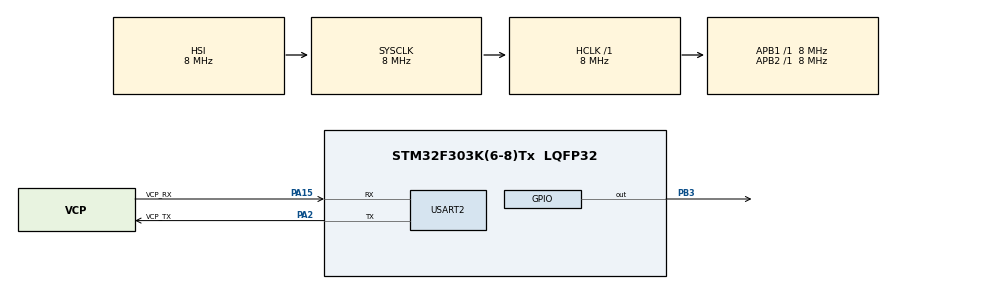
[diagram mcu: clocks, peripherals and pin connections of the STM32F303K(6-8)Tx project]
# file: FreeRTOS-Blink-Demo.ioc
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FREERTOS.Tasks01=blink01,24,128,StartBlink01,Default,NULL,Dynamic,NULL,NULL;blink02,16,128,StartBlink02,Default,NULL,Dynamic,NULL,NULL
Mcu.Family=STM32F3
Mcu.Name=STM32F303K(6-8)Tx
Mcu.Package=LQFP32
NVIC.PriorityGroup=NVIC_PRIORITYGROUP_4
NVIC.TIM6_DAC1_IRQn=true\:0\:0\:false\:false\:true\:false\:false\:true
NVIC.TimeBase=TIM6_DAC1_IRQn
NVIC.TimeBaseIP=TIM6
PA13.GPIO_Label=SWDIO
PA13.Mode=Serial_Wire
PA13.Signal=SYS_JTMS-SWDIO
PA14.GPIO_Label=SWCLK
PA14.Mode=Serial_Wire
PA14.Signal=SYS_JTCK-SWCLK
PA15.GPIO_Label=VCP_RX
PA15.Mode=Asynchronous
PA15.Signal=USART2_RX
PA2.GPIO_Label=VCP_TX
PA2.Mode=Asynchronous
PA2.Signal=USART2_TX
PB3.Signal=GPIO_Output
PF0\ /\ OSC_IN.GPIO_Label=MCO
PF0\ /\ OSC_IN.Mode=HSE-External-Clock-Source
PF0\ /\ OSC_IN.Signal=RCC_OSC_IN
ProjectManager.HeapSize=0x200
ProjectManager.StackSize=0x400
ProjectManager.TargetToolchain=TrueSTUDIO
RCC.AHBFreq_Value=8000000
RCC.APB1Freq_Value=8000000
RCC.APB2Freq_Value=8000000
RCC.CortexFreq_Value=8000000
RCC.HSE_VALUE=8000000
RCC.HSI_VALUE=8000000
RCC.SYSCLKFreq_VALUE=8000000
USART2.VirtualMode-Asynchronous=VM_ASYNC
VP_FREERTOS_VS_CMSIS_V2.Mode=CMSIS_V2
VP_SYS_VS_tim6.Mode=TIM6
board=NUCLEO-F303K8

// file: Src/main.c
/* USER CODE BEGIN Header */
/**
  ******************************************************************************
  * @file           : main.c
  * @brief          : Main program body
  ******************************************************************************
  * @attention
  *
  * <h2><center>&copy; Copyright (c) 2020 STMicroelectronics.
  * All rights reserved.</center></h2>
  *
  * This software component is licensed by ST under Ultimate Liberty license
  * SLA0044, the "License"; You may not use this file except in compliance with
  * the License. You may obtain a copy of the License at:
  *                             www.st.com/SLA0044
  *
  ******************************************************************************
  */
/* USER CODE END Header */

#include "main.h"
#include "cmsis_os.h"
#include "usart.h"
#include "gpio.h"

void SystemClock_Config(void);
void MX_FREERTOS_Init(void);

int main(void)
{

  /* MCU Configuration--------------------------------------------------------*/

  /* Reset of all peripherals, Initializes the Flash interface and the Systick. */
  HAL_Init();

  /* Configure the system clock */
  SystemClock_Config();

  /* Initialize all configured peripherals */
  MX_GPIO_Init();
  MX_USART2_UART_Init();
  /* Init scheduler */
  osKernelInitialize();

  /* Call init function for freertos objects (in freertos.c) */
  MX_FREERTOS_Init();

  /* Start scheduler */
  osKernelStart();

  /* We should never get here as control is now taken by the scheduler */

  /* Infinite loop */
  while (1)
  {

  }
}

void SystemClock_Config(void)
{
  RCC_OscInitTypeDef RCC_OscInitStruct = {0};
  RCC_ClkInitTypeDef RCC_ClkInitStruct = {0};

  /** Initializes the CPU, AHB and APB busses clocks
  */
  RCC_OscInitStruct.OscillatorType = RCC_OSCILLATORTYPE_HSI;
  RCC_OscInitStruct.HSIState = RCC_HSI_ON;
  RCC_OscInitStruct.HSICalibrationValue = RCC_HSICALIBRATION_DEFAULT;
  RCC_OscInitStruct.PLL.PLLState = RCC_PLL_NONE;
  if (HAL_RCC_OscConfig(&RCC_OscInitStruct) != HAL_OK)
  {
    Error_Handler();
  }
  /** Initializes the CPU, AHB and APB busses clocks
  */
  RCC_ClkInitStruct.ClockType = RCC_CLOCKTYPE_HCLK|RCC_CLOCKTYPE_SYSCLK
                              |RCC_CLOCKTYPE_PCLK1|RCC_CLOCKTYPE_PCLK2;
  RCC_ClkInitStruct.SYSCLKSource = RCC_SYSCLKSOURCE_HSI;
  RCC_ClkInitStruct.AHBCLKDivider = RCC_SYSCLK_DIV1;
  RCC_ClkInitStruct.APB1CLKDivider = RCC_HCLK_DIV1;
  RCC_ClkInitStruct.APB2CLKDivider = RCC_HCLK_DIV1;

  if (HAL_RCC_ClockConfig(&RCC_ClkInitStruct, FLASH_LATENCY_0) != HAL_OK)
  {
    Error_Handler();
  }
}

void HAL_TIM_PeriodElapsedCallback(TIM_HandleTypeDef *htim)
{
  if (htim->Instance == TIM6) {
    HAL_IncTick();
  }
}

void Error_Handler(void)
{
}

/************************ (C) COPYRIGHT STMicroelectronics *****END OF FILE****/

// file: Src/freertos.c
/* USER CODE BEGIN Header */
/**
  ******************************************************************************
  * File Name          : freertos.c
  * Description        : Code for freertos applications
  ******************************************************************************
  * @attention
  *
  * <h2><center>&copy; Copyright (c) 2020 STMicroelectronics.
  * All rights reserved.</center></h2>
  *
  * This software component is licensed by ST under Ultimate Liberty license
  * SLA0044, the "License"; You may not use this file except in compliance with
  * the License. You may obtain a copy of the License at:
  *                             www.st.com/SLA0044
  *
  ******************************************************************************
  */
/* USER CODE END Header */

#include "FreeRTOS.h"
#include "task.h"
#include "main.h"
#include "cmsis_os.h"

/* Definitions for blink01 */
osThreadId_t blink01Handle;
const osThreadAttr_t blink01_attributes = {
  .name = "blink01",
  .priority = (osPriority_t) osPriorityNormal,
  .stack_size = 128
};
/* Definitions for blink02 */
osThreadId_t blink02Handle;
const osThreadAttr_t blink02_attributes = {
  .name = "blink02",
  .priority = (osPriority_t) osPriorityBelowNormal,
  .stack_size = 128
};

void StartBlink01(void *argument);
void StartBlink02(void *argument);

void MX_FREERTOS_Init(void); /* (MISRA C 2004 rule 8.1) */

void MX_FREERTOS_Init(void) {

  /* Create the thread(s) */
  /* creation of blink01 */
  blink01Handle = osThreadNew(StartBlink01, NULL, &blink01_attributes);

  /* creation of blink02 */
  blink02Handle = osThreadNew(StartBlink02, NULL, &blink02_attributes);

}

void StartBlink01(void *argument)
{
  /* USER CODE BEGIN StartBlink01 */
  /* Infinite loop */
  for(;;)
  {
    osDelay(500);
    HAL_GPIO_TogglePin(GPIOB, GPIO_PIN_3);
  }

  //in case we accidentally exit from task loop
  osThreadTerminate(NULL);

  /* USER CODE END StartBlink01 */
}

void StartBlink02(void *argument)
{
  /* USER CODE BEGIN StartBlink02 */
  /* Infinite loop */
  for(;;)
  {
    osDelay(600);
    HAL_GPIO_TogglePin(GPIOB, GPIO_PIN_3);
  }

  //in case we accidentally exit from task loop
  osThreadTerminate(NULL);
  /* USER CODE END StartBlink02 */
}

/************************ (C) COPYRIGHT STMicroelectronics *****END OF FILE****/
